# ATxmega64D4 device description
Architecture: AVR8_XMEGA; Family: AVR XMEGA
Registers are 8-bit, access not given, no defined reset value unless marked. A register's access mark holds for its fields unless they carry their own. Offsets are from the block's base; [hi:lo] are bit positions; {n}, {i} and the like mark numbered series; 'fields as' and 'values as' point back to an identical list.

## CRC — Cyclic Redundancy Checker
Instances: CRC 0x0D0
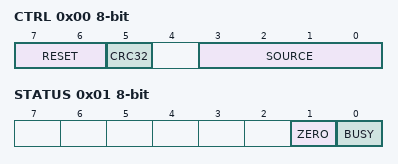
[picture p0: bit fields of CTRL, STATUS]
0x00 CTRL — Control Register
  [7:6] RESET
    0=NO (No Reset); 2=Reset CRC with CHECKSUM to all zeros; 3=Reset CRC with CHECKSUM to all ones
  [5] CRC32 — CRC Mode
  [3:0] SOURCE — Input Source
    0=DISABLE (Disabled); 1=IO (I/O Interface); 2=FLASH
0x01 STATUS
  [1] ZERO — Zero detection
  [0] BUSY
0x03 DATAIN — Data Input
{0x4+i} CHECKSUM{i} (i=0..3) — Checksum byte {i}

## EVSYS — Event System
Instances: EVSYS 0x0180
{0x0+i} CH{i}MUX (i=0..3) — Event Channel {i} Multiplexer
  [7:0] CHMUX
    0=OFF; 8=RTC_OVF (RTC Overflow); 9=RTC_CMP (RTC Compare Match); 16=ACA_CH0 (Analog Comparator A Channel 0); 17=ACA_CH1 (Analog Comparator A Channel 1); 18=ACA_WIN (Analog Comparator A Window); 32=ADCA_CH0 (ADC A Channel 0); {v}=PORTA_PIN{v-80} (v=80..87); {v}=PORTB_PIN{v-88} (v=88..95); {v}=PORTC_PIN{v-96} (v=96..103); {v}=PORTD_PIN{v-104} (v=104..111); {v}=PORTE_PIN{v-112} (v=112..119); {v}=PORTF_PIN{v-120} (v=120..127); 128=PRESCALER_1 (Prescaler, divide by 1); 129=PRESCALER_2 (Prescaler, divide by 2); 130=PRESCALER_4 (Prescaler, divide by 4); 131=PRESCALER_8 (Prescaler, divide by 8); 132=PRESCALER_16 (Prescaler, divide by 16); 133=PRESCALER_32 (Prescaler, divide by 32); 134=PRESCALER_64 (Prescaler, divide by 64); 135=PRESCALER_128 (Prescaler, divide by 128); 136=PRESCALER_256 (Prescaler, divide by 256); 137=PRESCALER_512 (Prescaler, divide by 512); 138=PRESCALER_1024 (Prescaler, divide by 1024); 139=PRESCALER_2048 (Prescaler, divide by 2048); 140=PRESCALER_4096 (Prescaler, divide by 4096); 141=PRESCALER_8192 (Prescaler, divide by 8192); 142=PRESCALER_16384 (Prescaler, divide by 16384); 143=PRESCALER_32768 (Prescaler, divide by 32768); 192=TCC0_OVF (Timer/Counter C0 Overflow); 193=TCC0_ERR (Timer/Counter C0 Error); 196=TCC0_CCA (Timer/Counter C0 Compare or Capture A); 197=TCC0_CCB (Timer/Counter C0 Compare or Capture B); 198=TCC0_CCC (Timer/Counter C0 Compare or Capture C); 199=TCC0_CCD (Timer/Counter C0 Compare or Capture D); 200=TCC1_OVF (Timer/Counter C1 Overflow); 201=TCC1_ERR (Timer/Counter C1 Error); 204=TCC1_CCA (Timer/Counter C1 Compare or Capture A); 205=TCC1_CCB (Timer/Counter C1 Compare or Capture B); 208=TCD0_OVF (Timer/Counter D0 Overflow); 209=TCD0_ERR (Timer/Counter D0 Error); 212=TCD0_CCA (Timer/Counter D0 Compare or Capture A); 213=TCD0_CCB (Timer/Counter D0 Compare or Capture B); 214=TCD0_CCC (Timer/Counter D0 Compare or Capture C); 215=TCD0_CCD (Timer/Counter D0 Compare or Capture D); 224=TCE0_OVF (Timer/Counter E0 Overflow); 225=TCE0_ERR (Timer/Counter E0 Error); 228=TCE0_CCA (Timer/Counter E0 Compare or Capture A); 229=TCE0_CCB (Timer/Counter E0 Compare or Capture B); 230=TCE0_CCC (Timer/Counter E0 Compare or Capture C); 231=TCE0_CCD (Timer/Counter E0 Compare or Capture D); 240=TCF0_OVF (Timer/Counter F0 Overflow); 241=TCF0_ERR (Timer/Counter F0 Error); 244=TCF0_CCA (Timer/Counter F0 Compare or Capture A); 245=TCF0_CCB (Timer/Counter F0 Compare or Capture B); 246=TCF0_CCC (Timer/Counter F0 Compare or Capture C); 247=TCF0_CCD (Timer/Counter F0 Compare or Capture D)
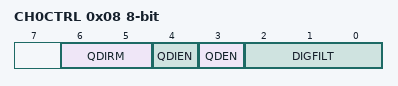
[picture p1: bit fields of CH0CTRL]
0x08 CH0CTRL — Channel 0 Control Register
  [6:5] QDIRM — Quadrature Decoder Index Recognition Mode
    0=QDPH0 = 0, QDPH90 = 0; 1=QDPH0 = 0, QDPH90 = 1; 2=QDPH0 = 1, QDPH90 = 0; 3=QDPH0 = 1, QDPH90 = 1
  [4] QDIEN — Quadrature Decoder Index Enable
  [3] QDEN — Quadrature Decoder Enable
  [2:0] DIGFILT — Digital Filter
    0=1SAMPLE; {v}={v+1}SAMPLES (v=1..7)
{0x8+i} CH{i}CTRL (i=1..3) — Channel {i} Control Register
  [2:0] DIGFILT — Digital Filter
    0=1SAMPLE; {v}={v+1}SAMPLES (v=1..7)
0x10 STROBE — Event Strobe
0x11 DATA — Event Data

## NVM — Non-volatile Memory Controller
Instances: NVM 0x01C0
{0x0+i} ADDR{i} (i=0..2) — Address Register {i}
{0x4+i} DATA{i} (i=0..2) — Data Register {i}
0x0A CMD — Command
  [6:0] CMD
    0=NO_OPERATION (Noop/Ordinary LPM); 1=READ_USER_SIG_ROW (Read user signature row); 2=READ_CALIB_ROW (Read calibration row); 6=READ_EEPROM; 7=READ_FUSES (Read fuse byte); 8=WRITE_LOCK_BITS; 24=ERASE_USER_SIG_ROW (Erase user signature row); 26=WRITE_USER_SIG_ROW (Write user signature row); 32=ERASE_APP (Erase Application Section); 34=ERASE_APP_PAGE (Erase Application Section page); 35=LOAD_FLASH_BUFFER (Load Flash page buffer); 36=WRITE_APP_PAGE (Write Application Section page); 37=ERASE_WRITE_APP_PAGE (Erase-and-write Application Section page); 38=ERASE_FLASH_BUFFER (Erase/flush Flash page buffer); 42=ERASE_BOOT_PAGE (Erase Boot Section page); 43=ERASE_FLASH_PAGE; 44=WRITE_BOOT_PAGE (Write Boot Section page); 45=ERASE_WRITE_BOOT_PAGE (Erase-and-write Boot Section page); 46=WRITE_FLASH_PAGE; 47=ERASE_WRITE_FLASH_PAGE (Erase-and-write Flash Page); 48=ERASE_EEPROM; 50=ERASE_EEPROM_PAGE; 51=LOAD_EEPROM_BUFFER (Load EEPROM page buffer); 52=WRITE_EEPROM_PAGE; 53=ERASE_WRITE_EEPROM_PAGE (Erase-and-write EEPROM page); 54=ERASE_EEPROM_BUFFER (Erase/flush EEPROM page buffer); 56=APP_CRC (Application section CRC); 57=BOOT_CRC (Boot Section CRC); 58=FLASH_RANGE_CRC; 64=CHIP_ERASE (Erase Chip); 67=READ_NVM; 76=WRITE_FUSE (Write Fuse byte); 104=ERASE_BOOT (Erase Boot Section); 120=FLASH_CRC
0x0B CTRLA — Control Register A
  [0] CMDEX — Command Execute
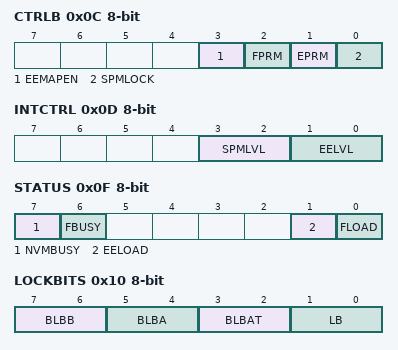
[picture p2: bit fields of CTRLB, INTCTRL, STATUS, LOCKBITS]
0x0C CTRLB — Control Register B
  [3] EEMAPEN — EEPROM Mapping Enable
  [2] FPRM — Flash Power Reduction Enable
  [1] EPRM — EEPROM Power Reduction Enable
  [0] SPMLOCK
0x0D INTCTRL — Interrupt Control
  [3:2] SPMLVL — SPM Interrupt Level
    0=OFF (Interrupt disabled); 1=LO (Low level); 2=MED (Medium level); 3=HI (High level)
  [1:0] EELVL — EEPROM Interrupt Level
    values as SPMLVL
0x0F STATUS
  [7] NVMBUSY — Non-volatile Memory Busy
  [6] FBUSY — Flash Memory Busy
  [1] EELOAD — EEPROM Page Buffer Active Loading
  [0] FLOAD — Flash Page Buffer Active Loading
0x10 LOCKBITS
  [7:6] BLBB — Boot Lock Bits - Boot Section
    0=RWLOCK (Read and write not allowed); 1=RLOCK (Read not allowed); 2=WLOCK (Write not allowed); 3=NOLOCK (No locks)
  [5:4] BLBA — Boot Lock Bits - Application Section
    values as BLBB
  [3:2] BLBAT — Boot Lock Bits - Application Table
    values as BLBB
  [1:0] LB — Lock Bits
    0=RWLOCK (Read and write not allowed); 2=WLOCK (Write not allowed); 3=NOLOCK (No locks)
